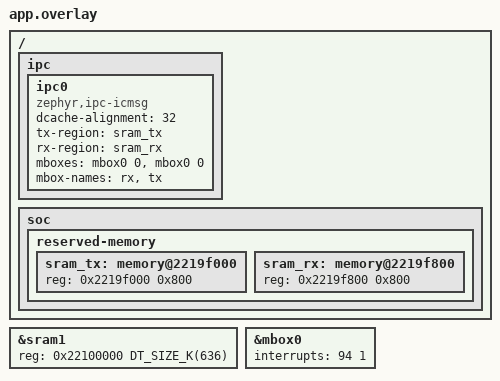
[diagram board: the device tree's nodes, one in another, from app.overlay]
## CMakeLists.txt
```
cmake_minimum_required(VERSION 3.20.0)
find_package(Zephyr REQUIRED HINTS $ENV{ZEPHYR_BASE})
project(titan_mini_rpmsg_remote)

target_sources(app PRIVATE src/main.c)
```

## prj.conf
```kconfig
# CM33 副核: 调试控制台走 uart2 (H1 排针, CM85 侧已让出), IPC echo
CONFIG_SERIAL=y
CONFIG_CONSOLE=y
CONFIG_UART_CONSOLE=y
CONFIG_UART_INTERRUPT_DRIVEN=y
CONFIG_PRINTK=y

# CM33 shell (跑在 uart2 上, 与 CM85 的 uart1 互不相干)
CONFIG_SHELL=y
CONFIG_SHELL_BACKEND_SERIAL=y

CONFIG_IPC_SERVICE=y
CONFIG_IPC_SERVICE_BACKEND_ICMSG=y
CONFIG_MBOX=y
CONFIG_LOG=n
```

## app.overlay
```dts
/*
 * CM33 侧 IPC: 与 CM85 app.overlay 镜像 (tx/rx 对调)
 */
/ {
	ipc {
		ipc0: ipc0 {
			compatible = "zephyr,ipc-icmsg";
			dcache-alignment = <32>;
			tx-region = <&sram_tx>;
			rx-region = <&sram_rx>;
			mboxes = <&mbox0 0>, <&mbox0 0>;
			mbox-names = "rx", "tx";
			status = "okay";
		};
	};

	soc {
		reserved-memory {
			#address-cells = <1>;
			#size-cells = <1>;

			sram_tx: memory@2219f000 {
				reg = <0x2219f000 0x800>;
			};

			sram_rx: memory@2219f800 {
				reg = <0x2219f800 0x800>;
			};
		};
	};
};

/* IPC 区在 sram1 顶部, 缩掉避免使用冲突 */
&sram1 {
	reg = <0x22100000 DT_SIZE_K(636)>;
};

&mbox0 {
	interrupts = <94 1>;
	status = "okay";
};
```

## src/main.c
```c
/*
 * Copyright (c) 2026 Titan Mini contributors
 * SPDX-License-Identifier: Apache-2.0
 *
 * Titan Mini 双核 RPMsg echo (CM33 副核):
 * 收到任意消息原样 echo 回去; 绑定成功后先发一条开机问候.
 */

#include <zephyr/kernel.h>
#include <zephyr/ipc/ipc_service.h>
#include <zephyr/sys/printk.h>
#include <zephyr/sys/util.h>
#include <string.h>

static const struct device *ipc0_dev = DEVICE_DT_GET(DT_NODELABEL(ipc0));
static struct ipc_ept ept;
static K_SEM_DEFINE(bound_sem, 0, 1);

static void ep_recv(const void *data, size_t len, void *priv)
{
	char buf[64];

	len = MIN(len, sizeof(buf) - 1);
	memcpy(buf, data, len);
	buf[len] = '\0';
	printk("CM33 RX (%zu bytes): %s\n", len, buf);

	/* echo 回 CM85 */
	(void)ipc_service_send(&ept, data, len);
}

static void ep_bound(void *priv)
{
	k_sem_give(&bound_sem);
}

static struct ipc_ept_cfg ep_cfg = {
	.name = "titan",
	.cb = {
		.bound = ep_bound,
		.received = ep_recv,
	},
};

int main(void)
{
	printk("CM33 (secondary core) booted, console on uart2\n");

	if (!device_is_ready(ipc0_dev)) {
		return -ENODEV;
	}

	int ret = ipc_service_open_instance(ipc0_dev);

	if (ret < 0 && ret != -EALREADY) {
		return ret;
	}

	ret = ipc_service_register_endpoint(ipc0_dev, &ept, &ep_cfg);
	if (ret < 0) {
		return ret;
	}

	k_sem_take(&bound_sem, K_FOREVER);

	/* 开机问候: CM85 会收到并打印 */
	static const char hello[] = "hello from cm33";

	(void)ipc_service_send(&ept, hello, sizeof(hello) - 1);

	while (1) {
		k_sleep(K_FOREVER);
	}
	return 0;
}
```
